AUTOSAR XML (schema 4-0-3)
package /ComponentTypes
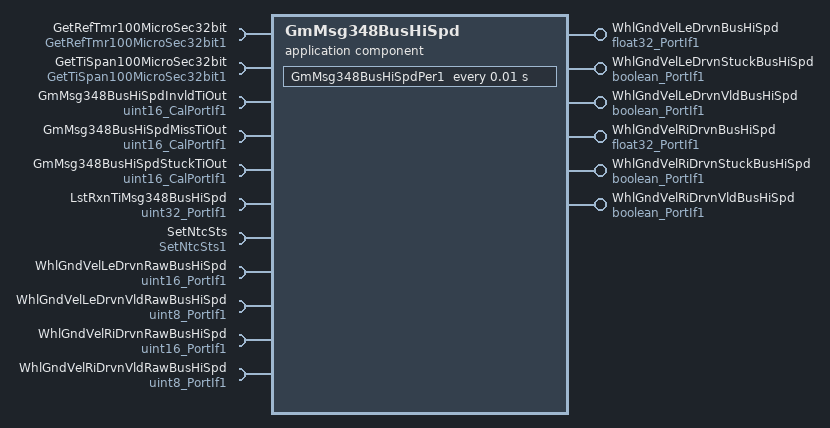
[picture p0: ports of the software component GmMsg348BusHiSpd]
  application sw component type GmMsg348BusHiSpd
    6 x provide port:
      WhlGndVelLeDrvnBusHiSpd: nonqueued-sender-com-spec{data-element=Val, init-value=0}, provided-interface=float32_PortIf1
      WhlGndVelLeDrvnStuckBusHiSpd: nonqueued-sender-com-spec{data-element=Logl, init-value=0}, provided-interface=boolean_PortIf1
      WhlGndVelLeDrvnVldBusHiSpd: nonqueued-sender-com-spec{data-element=Logl, init-value=0}, provided-interface=boolean_PortIf1
      WhlGndVelRiDrvnBusHiSpd: nonqueued-sender-com-spec{data-element=Val, init-value=0}, provided-interface=float32_PortIf1
      WhlGndVelRiDrvnStuckBusHiSpd: nonqueued-sender-com-spec{data-element=Logl, init-value=0}, provided-interface=boolean_PortIf1
      WhlGndVelRiDrvnVldBusHiSpd: nonqueued-sender-com-spec{data-element=Logl, init-value=0}, provided-interface=boolean_PortIf1
    11 x require port:
      GetRefTmr100MicroSec32bit: required-interface=GetRefTmr100MicroSec32bit1
      GetTiSpan100MicroSec32bit: required-interface=GetTiSpan100MicroSec32bit1
      GmMsg348BusHiSpdInvldTiOut: parameter-require-com-spec{init-value=1000, parameter=Val}, required-interface=uint16_CalPortIf1
      GmMsg348BusHiSpdMissTiOut: parameter-require-com-spec{init-value=500, parameter=Val}, required-interface=uint16_CalPortIf1
      GmMsg348BusHiSpdStuckTiOut: parameter-require-com-spec{init-value=500, parameter=Val}, required-interface=uint16_CalPortIf1
      LstRxnTiMsg348BusHiSpd: nonqueued-receiver-com-spec{data-element=Val, filter=data-filter-type=ALWAYS, init-value=0}, required-interface=uint32_PortIf1
      SetNtcSts: required-interface=SetNtcSts1
      WhlGndVelLeDrvnRawBusHiSpd: nonqueued-receiver-com-spec{data-element=Val, filter=data-filter-type=ALWAYS, init-value=0}, required-interface=uint16_PortIf1
      WhlGndVelLeDrvnVldRawBusHiSpd: nonqueued-receiver-com-spec{data-element=Val, filter=data-filter-type=ALWAYS, init-value=0}, required-interface=uint8_PortIf1
      WhlGndVelRiDrvnRawBusHiSpd: nonqueued-receiver-com-spec{data-element=Val, filter=data-filter-type=ALWAYS, init-value=0}, required-interface=uint16_PortIf1
      WhlGndVelRiDrvnVldRawBusHiSpd: nonqueued-receiver-com-spec{data-element=Val, filter=data-filter-type=ALWAYS, init-value=0}, required-interface=uint8_PortIf1
    behavior GmMsg348BusHiSpd_InternalBehavior: data-type-mapping=Nexteer
      ar-typed-per-instance-memorys:
        6 x data, all with sw-calibration-access=READ-ONLY:
          GmMsg348BusHiSpdPrevWhlGndVelLeDrvn: type=uint16
          GmMsg348BusHiSpdPrevWhlGndVelRiDrvn: type=uint16
          GmMsg348BusHiSpdWhlGndVelLeDrvnInvldTi: type=uint32
          GmMsg348BusHiSpdWhlGndVelLeDrvnStuckTi: type=uint32
          GmMsg348BusHiSpdWhlGndVelRiDrvnInvldTi: type=uint32
          GmMsg348BusHiSpdWhlGndVelRiDrvnStuckTi: type=uint32
      timing event TMT_GM0C9HSPer1: start-on-event=GmMsg348BusHiSpdPer1, period=0.01
      runnable GmMsg348BusHiSpdPer1
        data-receive-point-by-arguments:
          5 x access:
            REC_HiSpdWhlGndVelLeDrvn_Val: accessed-variable=WhlGndVelLeDrvnRawBusHiSpd.Val
            REC_HiSpdWhlGndVelLeDrvnVld_Val: accessed-variable=WhlGndVelLeDrvnVldRawBusHiSpd.Val
            REC_HiSpdWhlGndVelRiDrvn_Val: accessed-variable=WhlGndVelRiDrvnRawBusHiSpd.Val
            REC_HiSpdWhlGndVelRiDrvnVld_Val: accessed-variable=WhlGndVelRiDrvnVldRawBusHiSpd.Val
            REC_Msg348HSLstRxnTi_Val: accessed-variable=LstRxnTiMsg348BusHiSpd.Val
        data-send-points:
          6 x access:
            SEND_GM348HSWhlGndVelLeDrvn_Val: accessed-variable=WhlGndVelLeDrvnBusHiSpd.Val
            SEND_GM348HSWhlGndVelLeDrvnVld_Logl: accessed-variable=WhlGndVelLeDrvnVldBusHiSpd.Logl
            SEND_GM348HSWhlGndVelRiDrvn_Val: accessed-variable=WhlGndVelRiDrvnBusHiSpd.Val
            SEND_GM348HSWhlGndVelRiDrvnVld_Logl: accessed-variable=WhlGndVelRiDrvnVldBusHiSpd.Logl
            SEND_WhlGndVelLeDrvnStuckBusHiSpd_Logl: accessed-variable=WhlGndVelLeDrvnStuckBusHiSpd.Logl
            SEND_WhlGndVelRiDrvnStuckBusHiSpd_Logl: accessed-variable=WhlGndVelRiDrvnStuckBusHiSpd.Logl
        sync call SC_GetRefTmr100MicroSec32bit_Oper: operation=GetRefTmr100MicroSec32bit.Oper, timeout=0
        sync call SC_GetTiSpan100MicroSec32bit_Oper: operation=GetTiSpan100MicroSec32bit.Oper, timeout=0
        sync call SC_SetNtcSts_Oper: operation=SetNtcSts.Oper, timeout=0
  swc implementation GmMsg348BusHiSpd_Implementation: behavior=GmMsg348BusHiSpd_InternalBehavior
    code-descriptors:
      code Default: artifact-descriptors=autosar-engineering-object={short-label=Default, category=SWSRC}
